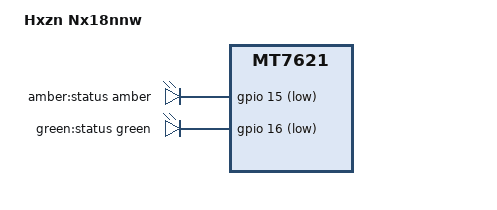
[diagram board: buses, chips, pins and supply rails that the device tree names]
#include "mt7621_hxzn_nx18nnw_128m.dtsi"

/ {
	compatible = "hxzn,nx18nnw", "mediatek,mt7621-soc";
	model = "Hxzn Nx18nnw";

	aliases {
		led-boot = &led_status_yellow;
		led-failsafe = &led_status_red;
		led-running = &led_status_blue;
		led-upgrade = &led_status_yellow;
		label-mac-device = &gmac0;
	};

	leds {
		compatible = "gpio-leds";

		led_status_amber: led-0 {
			label = "amber:status";
			color = <LED_COLOR_ID_AMBER>;
			function = LED_FUNCTION_STATUS;
			gpios = <&gpio 15 GPIO_ACTIVE_LOW>;
		};

		led_status_green: led-1 {
			label = "green:status";
			color = <LED_COLOR_ID_GREEN>;
			function = LED_FUNCTION_STATUS;
			gpios = <&gpio 16 GPIO_ACTIVE_LOW>;
		};
	};
};
